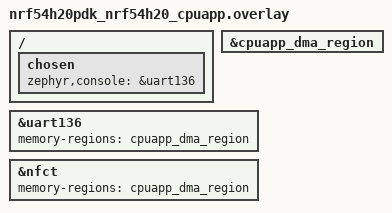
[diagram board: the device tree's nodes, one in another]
/*
 * Copyright (c) 2023 Nordic Semiconductor ASA
 *
 * SPDX-License-Identifier: LicenseRef-Nordic-5-Clause
 */

/ {
	chosen {
		zephyr,console = &uart136;
	};
};

&cpuapp_dma_region {
	status = "okay";
};

&uart136 {
	status = "okay";
	memory-regions = <&cpuapp_dma_region>;
};

&nfct {
	status = "okay";
	memory-regions = <&cpuapp_dma_region>;
};
